# NPCX490M register map
File version: 1.0
Registers are 8-bit, read-write, reset 0x0 unless marked. A register's access mark holds for its fields unless they carry their own. Offsets are from the block's base; [hi:lo] are bit positions; {n}, {i} and the like mark numbered series.

## PWM0
Base 0x40080000
Same registers: PWM1 0x40082000, PWM2 0x40084000, PWM3 0x40086000, PWM4 0x40088000, PWM5 0x4008A000, PWM6 0x4008C000, PWM7 0x4008E000
0x00 PRSCn 16-bit (reset mask 0xFF) — Clock Prescaler Register (PRSCn)
0x02 CTR_RSn 16-bit (reset mask 0xFF) — Cycle Time for Rise Duty Cycle Register (CTR_RSn)
  [11:0] CTR_RS11_0 — Cycle Time Value for Rise Duty Cycle
0x02 CTRn 16-bit (reset mask 0xFF) — Cycle Time Register (CTRn)
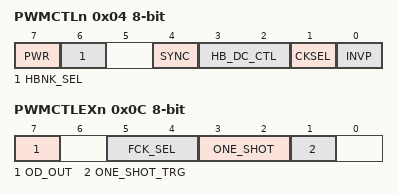
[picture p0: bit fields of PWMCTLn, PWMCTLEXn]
0x04 PWMCTLn — PWM Control Register (PWMCTLn)
  [7] PWR — Power Mode
  [6] HBNK_SEL — Heartbeat Bank Select
  [4] SYNC — Operation Synchronization
  [3:2] HB_DC_CTL — Heartbeat Duty Cycle Control
  [1] CKSEL — Input Clock Select
  [0] INVP — Inverse PWM Output
0x05 N_STEP_RSn — Number of Steps for Rise Duty Cycle Register (N_STEP_RSn)
0x06 MAX_DC_RSn 16-bit (reset mask 0xFF) — Maximum Duty Cycle Rise Register (MAX_DC_RSn)
  [11:0] MAX_DC_RS11_0 — Maximum Duty Cycle Rise Value
0x06 DCRn 16-bit (reset mask 0xFF) — Duty Cycle Register (DCRn)
0x08 CTR_FLn 16-bit (reset mask 0xFF) — Cycle Time for Fall Duty Cycle Register (CTR_FLn)
  [11:0] CTR_FL11_0 — Cycle Time Value for Fall Duty Cycle
0x0A MAX_DC_FLn 16-bit (reset mask 0xFF) — Maximum Duty Cycle Fall Register (MAX_DC_FLn)
  [11:0] MAX_DC_FL11_0 — Maximum Duty Cycle Fall Value
0x0C PWMCTLEXn — PWM Control Extended Register (PWMCTLEXn)
  [7] OD_OUT — Open-Drain Output
  [5:4] FCK_SEL — Fixed Frequency Clock Select
  [3:2] ONE_SHOT — One-Shot Mode
  [1] ONE_SHOT_TRG — One-Shot Trigger
0x0D N_STEP_FLn — Number of Steps for Fall Duty Cycle Register (N_STEP_FLn)
0x0E EXT_ONn — Extend ON Time Register (EXT_ONn)
0x0F EXT_OFFn — Extend OFF Time Register (EXT_OFFn)
0x10 MIN_DC_RSFLn 16-bit (reset mask 0xFF) — Minimum Duty Cycle Rise/Fall Register (MIN_DC_RSFLn)
  [11:0] MIN_DC_RSFL11_0 — Minimum Duty Cycle Rise/Fall Value

## SHI
Base 0x4000F000
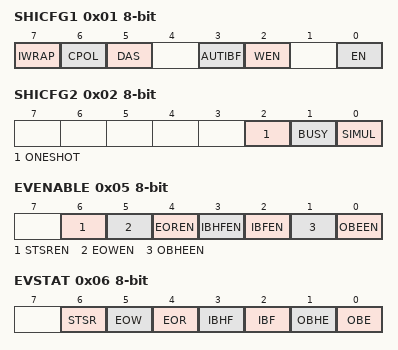
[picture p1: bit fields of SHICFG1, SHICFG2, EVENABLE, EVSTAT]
0x01 SHICFG1 — SHI Configuration 1
  [7] IWRAP — Input Buffer Wraparound Enable
  [6] CPOL — Clock Polarity
  [5] DAS — Data after Status
  [3] AUTIBF — Automatic Input Buffer Full Indication
  [2] WEN — Host Write Enable
  [0] EN — SHI Enable
0x02 SHICFG2 — SHI Configuration 2
  [2] ONESHOT — Write One Shot
  [1] BUSY — SHI Busy
  [0] SIMUL — Simultaneous Read/Write
0x05 EVENABLE — Event Enable
  [6] STSREN — Status Read Interrupt Enable
  [5] EOWEN — End-of-Data for Write Transaction Interrupt Enable
  [4] EOREN — End-of-Data for Read Transaction Interrupt Enable
  [3] IBHFEN — Input Buffer Half Full Interrupt Enable
  [2] IBFEN — Input Buffer Full Interrupt Enable
  [1] OBHEEN — 128-Byte Payload Buffer Half Empty Interrupt Enable
  [0] OBEEN — 128-Byte Payload Buffer Empty Interrupt Enable
0x06 EVSTAT — Event Status
  [6] STSR — Status Read
  [5] EOW — End-of-Data for Write Transaction
  [4] EOR — End-of-Data for Read Transaction
  [3] IBHF — Input Buffer Half Full
  [2] IBF — Input Buffer Full
  [1] OBHE — 128-Byte Payload Buffer Half Empty
  [0] OBE — 128-Byte Payload Buffer Empty
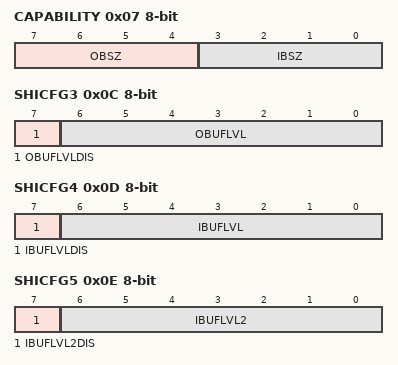
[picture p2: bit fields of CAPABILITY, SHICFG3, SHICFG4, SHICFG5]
0x07 CAPABILITY — SHI Capabilities
  [7:4] OBSZ — 128-Byte Payload Buffer Size
  [3:0] IBSZ — Input Buffer Size
0x08 STATUS
  [7] IBFS — Input Buffer Full Status
0x0A IBUFSTAT — Input Buffer Status
0x0B OBUFSTAT — Output Buffer Status
0x0C SHICFG3 — SHI Configuration 3
  [7] OBUFLVLDIS — 128-Byte Payload Buffer Level Disabled
  [6:0] OBUFLVL — 128-Byte Payload Buffer Level
0x0D SHICFG4 — SHI Configuration 4
  [7] IBUFLVLDIS — Input Buffer Level Disabled
  [6:0] IBUFLVL — Input Buffer Level
0x0E SHICFG5 — SHI Configuration 5
  [7] IBUFLVL2DIS — Input Buffer Level 2 Disabled
  [6:0] IBUFLVL2 — Input Buffer Level 2
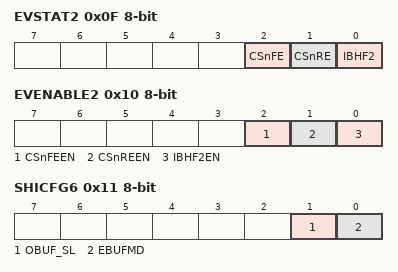
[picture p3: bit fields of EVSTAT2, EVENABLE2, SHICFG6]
0x0F EVSTAT2 — Event Status 2
  [2] CSnFE — SHI_CS Falling Edge
  [1] CSnRE — SHI_CS Rising Edge
  [0] IBHF2 — Input Buffer Half Full 2
0x10 EVENABLE2 — Event Enable 2
  [2] CSnFEEN — SHI_CS Falling Edge Interrupt Enable
  [1] CSnREEN — SHI_CS Rising Edge Interrupt Enable
  [0] IBHF2EN — Input Buffer Half Full 2 Interrupt Enable
0x11 SHICFG6 — SHI Configuration 6
  [1] OBUF_SL — OBUF Select
  [0] EBUFMD — Enhanced Buffer Mode
0x12 SBOBUF — Single Byte Output Buffer
{0x20+i} OBUF{i} (i=0..127) — Output Buffer Register
{0xA0+i} IBUF{i} (i=0..127) — Input Buffer Register
